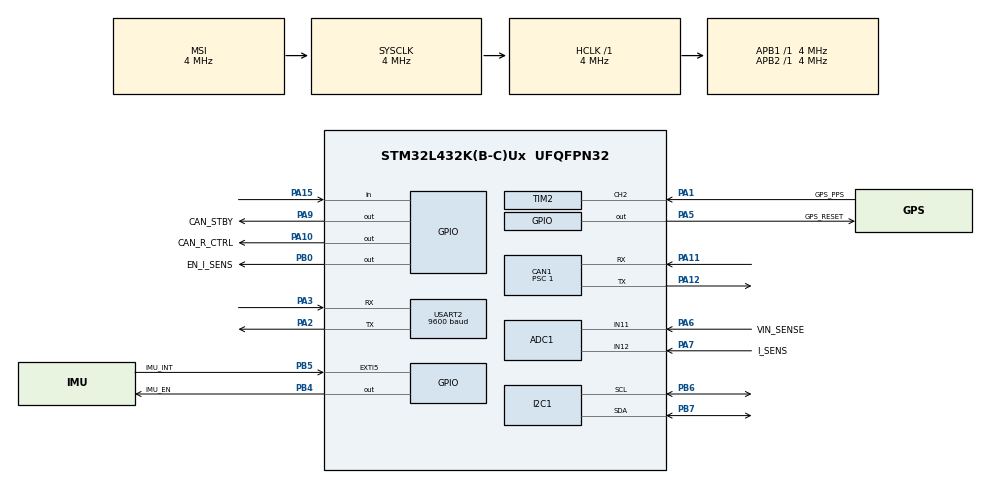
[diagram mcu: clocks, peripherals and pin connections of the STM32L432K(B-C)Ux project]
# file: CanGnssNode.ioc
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ADC1.Channel-0\#ChannelRegularConversion=ADC_CHANNEL_11
ADC1.Channel-1\#ChannelRegularConversion=ADC_CHANNEL_12
ADC1.Channel-2\#ChannelRegularConversion=ADC_CHANNEL_VREFINT
ADC1.Channel-3\#ChannelRegularConversion=ADC_CHANNEL_TEMPSENSOR
ADC1.NbrOfConversion=4
ADC1.NbrOfConversionFlag=1
ADC1.OffsetNumber-0\#ChannelRegularConversion=ADC_OFFSET_NONE
ADC1.OffsetNumber-1\#ChannelRegularConversion=ADC_OFFSET_NONE
ADC1.OffsetNumber-2\#ChannelRegularConversion=ADC_OFFSET_NONE
ADC1.OffsetNumber-3\#ChannelRegularConversion=ADC_OFFSET_NONE
ADC1.OversamplingMode=ENABLE
ADC1.Rank-0\#ChannelRegularConversion=1
ADC1.Rank-1\#ChannelRegularConversion=2
ADC1.Rank-2\#ChannelRegularConversion=3
ADC1.Rank-3\#ChannelRegularConversion=4
ADC1.Ratio=ADC_OVERSAMPLING_RATIO_16
ADC1.RightBitShift=ADC_RIGHTBITSHIFT_2
ADC1.SamplingTime-0\#ChannelRegularConversion=ADC_SAMPLETIME_640CYCLES_5
ADC1.SamplingTime-1\#ChannelRegularConversion=ADC_SAMPLETIME_247CYCLES_5
ADC1.SamplingTime-2\#ChannelRegularConversion=ADC_SAMPLETIME_640CYCLES_5
ADC1.SamplingTime-3\#ChannelRegularConversion=ADC_SAMPLETIME_640CYCLES_5
ADC1.master=1
CAN1.BS1=CAN_BS1_6TQ
CAN1.CalculateBaudRate=500000
CAN1.CalculateTimeBit=2000
CAN1.CalculateTimeQuantum=250.0
CAN1.NART=ENABLE
CAN1.Prescaler=1
CAN1.TTCM=ENABLE
CAN1.TXFP=ENABLE
Dma.ADC1.4.Direction=DMA_PERIPH_TO_MEMORY
Dma.ADC1.4.Instance=DMA1_Channel1
Dma.ADC1.4.MemDataAlignment=DMA_MDATAALIGN_HALFWORD
Dma.ADC1.4.MemInc=DMA_MINC_ENABLE
Dma.ADC1.4.Mode=DMA_NORMAL
Dma.ADC1.4.PeriphDataAlignment=DMA_PDATAALIGN_HALFWORD
Dma.ADC1.4.PeriphInc=DMA_PINC_DISABLE
Dma.ADC1.4.Priority=DMA_PRIORITY_LOW
Dma.I2C1_RX.2.Direction=DMA_PERIPH_TO_MEMORY
Dma.I2C1_RX.2.Instance=DMA2_Channel6
Dma.I2C1_RX.2.MemDataAlignment=DMA_MDATAALIGN_BYTE
Dma.I2C1_RX.2.MemInc=DMA_MINC_ENABLE
Dma.I2C1_RX.2.Mode=DMA_NORMAL
Dma.I2C1_RX.2.PeriphDataAlignment=DMA_PDATAALIGN_BYTE
Dma.I2C1_RX.2.PeriphInc=DMA_PINC_DISABLE
Dma.I2C1_RX.2.Priority=DMA_PRIORITY_LOW
Dma.I2C1_TX.3.Direction=DMA_MEMORY_TO_PERIPH
Dma.I2C1_TX.3.Instance=DMA2_Channel7
Dma.I2C1_TX.3.MemDataAlignment=DMA_MDATAALIGN_BYTE
Dma.I2C1_TX.3.MemInc=DMA_MINC_ENABLE
Dma.I2C1_TX.3.Mode=DMA_NORMAL
Dma.I2C1_TX.3.PeriphDataAlignment=DMA_PDATAALIGN_BYTE
Dma.I2C1_TX.3.PeriphInc=DMA_PINC_DISABLE
Dma.I2C1_TX.3.Priority=DMA_PRIORITY_LOW
Dma.Request0=USART2_RX
Dma.Request1=USART2_TX
Dma.Request2=I2C1_RX
Dma.Request3=I2C1_TX
Dma.Request4=ADC1
Dma.USART2_RX.0.Direction=DMA_PERIPH_TO_MEMORY
Dma.USART2_RX.0.Instance=DMA1_Channel6
Dma.USART2_RX.0.MemDataAlignment=DMA_MDATAALIGN_BYTE
Dma.USART2_RX.0.MemInc=DMA_MINC_ENABLE
Dma.USART2_RX.0.Mode=DMA_CIRCULAR
Dma.USART2_RX.0.PeriphDataAlignment=DMA_PDATAALIGN_BYTE
Dma.USART2_RX.0.PeriphInc=DMA_PINC_DISABLE
Dma.USART2_RX.0.Priority=DMA_PRIORITY_LOW
Dma.USART2_TX.1.Direction=DMA_MEMORY_TO_PERIPH
Dma.USART2_TX.1.Instance=DMA1_Channel7
Dma.USART2_TX.1.MemDataAlignment=DMA_MDATAALIGN_BYTE
Dma.USART2_TX.1.MemInc=DMA_MINC_ENABLE
Dma.USART2_TX.1.Mode=DMA_NORMAL
Dma.USART2_TX.1.PeriphDataAlignment=DMA_PDATAALIGN_BYTE
Dma.USART2_TX.1.PeriphInc=DMA_PINC_DISABLE
Dma.USART2_TX.1.Priority=DMA_PRIORITY_LOW
I2C1.Timing=0x00100D14
Mcu.Family=STM32L4
Mcu.Name=STM32L432K(B-C)Ux
Mcu.Package=UFQFPN32
NVIC.CAN1_RX0_IRQn=true\:0\:0\:false\:false\:true\:true\:true\:true
NVIC.CAN1_SCE_IRQn=true\:1\:0\:true\:false\:true\:true\:true\:true
NVIC.CAN1_TX_IRQn=true\:0\:0\:false\:false\:true\:true\:true\:true
NVIC.DMA1_Channel1_IRQn=true\:3\:0\:true\:false\:true\:false\:true\:true
NVIC.DMA1_Channel6_IRQn=true\:2\:0\:true\:false\:true\:false\:true\:true
NVIC.DMA1_Channel7_IRQn=true\:2\:0\:true\:false\:true\:false\:true\:true
NVIC.DMA2_Channel6_IRQn=true\:3\:0\:true\:false\:true\:false\:true\:true
NVIC.DMA2_Channel7_IRQn=true\:3\:0\:true\:false\:true\:false\:true\:true
NVIC.EXTI9_5_IRQn=true\:2\:0\:true\:false\:true\:true\:true\:true
NVIC.I2C1_ER_IRQn=true\:3\:0\:true\:false\:true\:true\:true\:true
NVIC.I2C1_EV_IRQn=true\:3\:0\:true\:false\:true\:true\:true\:true
NVIC.PriorityGroup=NVIC_PRIORITYGROUP_4
NVIC.TIM2_IRQn=true\:0\:0\:false\:false\:true\:true\:true\:true
NVIC.USART2_IRQn=true\:2\:0\:true\:false\:true\:true\:true\:true
PA1.GPIO_Label=GPS_PPS
PA1.Signal=S_TIM2_CH2
PA10.GPIO_Label=CAN_R_CTRL
PA10.GPIO_PuPd=GPIO_NOPULL
PA10.Signal=GPIO_Output
PA11.Mode=CAN_Activate
PA11.Signal=CAN1_RX
PA12.Mode=CAN_Activate
PA12.Signal=CAN1_TX
PA13\ (JTMS-SWDIO).GPIO_Label=SWDIO
PA13\ (JTMS-SWDIO).Mode=Trace_Asynchronous_SW
PA13\ (JTMS-SWDIO).Signal=SYS_JTMS-SWDIO
PA14\ (JTCK-SWCLK).GPIO_Label=SWCLK
PA14\ (JTCK-SWCLK).Mode=Trace_Asynchronous_SW
PA14\ (JTCK-SWCLK).Signal=SYS_JTCK-SWCLK
PA15\ (JTDI).Signal=GPIO_Input
PA2.Mode=Asynchronous
PA2.Signal=USART2_TX
PA3.Mode=Asynchronous
PA3.Signal=USART2_RX
PA5.GPIO_Label=GPS_RESET
PA5.GPIO_PuPd=GPIO_NOPULL
PA5.Signal=GPIO_Output
PA6.GPIO_Label=VIN_SENSE
PA6.Signal=ADCx_IN11
PA7.GPIO_Label=I_SENS
PA7.Signal=ADCx_IN12
PA9.GPIO_Label=CAN_STBY
PA9.GPIO_PuPd=GPIO_NOPULL
PA9.Signal=GPIO_Output
PB0.GPIO_Label=EN_I_SENS
PB0.GPIO_PuPd=GPIO_NOPULL
PB0.Signal=GPIO_Output
PB3\ (JTDO-TRACESWO).GPIO_Label=SWO
PB3\ (JTDO-TRACESWO).Mode=Trace_Asynchronous_SW
PB3\ (JTDO-TRACESWO).Signal=SYS_JTDO-SWO
PB4\ (NJTRST).GPIO_Label=IMU_EN
PB4\ (NJTRST).GPIO_PuPd=GPIO_NOPULL
PB4\ (NJTRST).Signal=GPIO_Output
PB5.GPIO_Label=IMU_INT
PB5.GPIO_ModeDefaultEXTI=GPIO_MODE_IT_FALLING
PB5.GPIO_PuPd=GPIO_PULLUP
PB5.Signal=GPXTI5
PB6.Mode=I2C
PB6.Signal=I2C1_SCL
PB7.Mode=I2C
PB7.Signal=I2C1_SDA
ProjectManager.HeapSize=0x200
ProjectManager.StackSize=0x400
ProjectManager.TargetToolchain=STM32CubeIDE
RCC.ADCCLockSelection=RCC_ADCCLKSOURCE_SYSCLK
RCC.ADCFreq_Value=4000000
RCC.AHBFreq_Value=4000000
RCC.APB1Freq_Value=4000000
RCC.APB1TimFreq_Value=4000000
RCC.APB2Freq_Value=4000000
RCC.APB2TimFreq_Value=4000000
RCC.CortexFreq_Value=4000000
RCC.HCLKFreq_Value=4000000
RCC.HSE_VALUE=8000000
RCC.HSI48_VALUE=48000000
RCC.HSI_VALUE=16000000
RCC.LSE_VALUE=32768
RCC.MSI_VALUE=4000000
RCC.PWR_Regulator_Voltage_Scale=PWR_REGULATOR_VOLTAGE_SCALE2
RCC.SYSCLKFreq_VALUE=4000000
RCC.USBFreq_Value=16000000
RCC.VCOOutputFreq_Value=32000000
SH.ADCx_IN11.0=ADC1_IN11,IN11-Single-Ended
SH.ADCx_IN12.0=ADC1_IN12,IN12-Single-Ended
SH.S_TIM2_CH2.0=TIM2_CH2,Input_Capture2_from_TI2
TIM2.Channel-Input_Capture2_from_TI2=TIM_CHANNEL_2
TIM2.ICFilter_CH2=4
USART2.BaudRate=9600
USART2.OverrunDisableParam=ADVFEATURE_OVERRUN_DISABLE
USART2.VirtualMode-Asynchronous=VM_ASYNC
VP_ADC1_TempSens_Input.Mode=IN-TempSens
VP_ADC1_Vref_Input.Mode=IN-Vrefint
VP_TIM2_VS_ClockSourceINT.Mode=Internal
board=custom

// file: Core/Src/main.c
/* USER CODE BEGIN Header */
/**
  ******************************************************************************
  * @file           : main.c
  * @brief          : Main program body
  ******************************************************************************
  * @attention
  *
  * Copyright (c) 2026 STMicroelectronics.
  * All rights reserved.
  *
  * This software is licensed under terms that can be found in the LICENSE file
  * in the root directory of this software component.
  * If no LICENSE file comes with this software, it is provided AS-IS.
  *
  ******************************************************************************
  */
/* USER CODE END Header */
#include "main.h"

ADC_HandleTypeDef hadc1;
DMA_HandleTypeDef hdma_adc1;

CAN_HandleTypeDef hcan1;

I2C_HandleTypeDef hi2c1;
DMA_HandleTypeDef hdma_i2c1_rx;
DMA_HandleTypeDef hdma_i2c1_tx;

TIM_HandleTypeDef htim2;

UART_HandleTypeDef huart2;
DMA_HandleTypeDef hdma_usart2_rx;
DMA_HandleTypeDef hdma_usart2_tx;

void SystemClock_Config(void);
static void MX_GPIO_Init(void);
static void MX_DMA_Init(void);
static void MX_ADC1_Init(void);
static void MX_CAN1_Init(void);
static void MX_I2C1_Init(void);
static void MX_USART2_UART_Init(void);
static void MX_TIM2_Init(void);

int main(void)
{

  /* USER CODE BEGIN 1 */
  /* Aplikacja jest zrelokowana za bootloaderem (0x08004000). Tablica wektorow
   * ustawiana przed HAL_Init, zanim wystartuja SysTick i przerwania. Tutaj,
   * a nie w system_stm32l4xx.c, zeby przetrwac regeneracje CubeMX. */
  SCB->VTOR = 0x08004000u;
  /* USER CODE END 1 */

  /* MCU Configuration--------------------------------------------------------*/

  /* Reset of all peripherals, Initializes the Flash interface and the Systick. */
  HAL_Init();

  /* Configure the system clock */
  SystemClock_Config();

  /* Initialize all configured peripherals */
  MX_GPIO_Init();
  MX_DMA_Init();
  MX_ADC1_Init();
  MX_CAN1_Init();
  MX_I2C1_Init();
  MX_USART2_UART_Init();
  MX_TIM2_Init();

  /* Infinite loop */
  while (1)
  {

  }
}

void SystemClock_Config(void)
{
  RCC_OscInitTypeDef RCC_OscInitStruct = {0};
  RCC_ClkInitTypeDef RCC_ClkInitStruct = {0};

  /** Configure the main internal regulator output voltage
  */
  if (HAL_PWREx_ControlVoltageScaling(PWR_REGULATOR_VOLTAGE_SCALE2) != HAL_OK)
  {
    Error_Handler();
  }

  /** Initializes the RCC Oscillators according to the specified parameters
  * in the RCC_OscInitTypeDef structure.
  */
  RCC_OscInitStruct.OscillatorType = RCC_OSCILLATORTYPE_MSI;
  RCC_OscInitStruct.MSIState = RCC_MSI_ON;
  RCC_OscInitStruct.MSICalibrationValue = 0;
  RCC_OscInitStruct.MSIClockRange = RCC_MSIRANGE_6;
  RCC_OscInitStruct.PLL.PLLState = RCC_PLL_NONE;
  if (HAL_RCC_OscConfig(&RCC_OscInitStruct) != HAL_OK)
  {
    Error_Handler();
  }

  /** Initializes the CPU, AHB and APB buses clocks
  */
  RCC_ClkInitStruct.ClockType = RCC_CLOCKTYPE_HCLK|RCC_CLOCKTYPE_SYSCLK
                              |RCC_CLOCKTYPE_PCLK1|RCC_CLOCKTYPE_PCLK2;
  RCC_ClkInitStruct.SYSCLKSource = RCC_SYSCLKSOURCE_MSI;
  RCC_ClkInitStruct.AHBCLKDivider = RCC_SYSCLK_DIV1;
  RCC_ClkInitStruct.APB1CLKDivider = RCC_HCLK_DIV1;
  RCC_ClkInitStruct.APB2CLKDivider = RCC_HCLK_DIV1;

  if (HAL_RCC_ClockConfig(&RCC_ClkInitStruct, FLASH_LATENCY_0) != HAL_OK)
  {
    Error_Handler();
  }
}

static void MX_ADC1_Init(void)
{

  ADC_ChannelConfTypeDef sConfig = {0};

  /** Common config
  */
  hadc1.Instance = ADC1;
  hadc1.Init.ClockPrescaler = ADC_CLOCK_ASYNC_DIV1;
  hadc1.Init.Resolution = ADC_RESOLUTION_12B;
  hadc1.Init.DataAlign = ADC_DATAALIGN_RIGHT;
  hadc1.Init.ScanConvMode = ADC_SCAN_ENABLE;
  hadc1.Init.EOCSelection = ADC_EOC_SINGLE_CONV;
  hadc1.Init.LowPowerAutoWait = DISABLE;
  hadc1.Init.ContinuousConvMode = DISABLE;
  hadc1.Init.NbrOfConversion = 4;
  hadc1.Init.DiscontinuousConvMode = DISABLE;
  hadc1.Init.ExternalTrigConv = ADC_SOFTWARE_START;
  hadc1.Init.ExternalTrigConvEdge = ADC_EXTERNALTRIGCONVEDGE_NONE;
  hadc1.Init.DMAContinuousRequests = DISABLE;
  hadc1.Init.Overrun = ADC_OVR_DATA_PRESERVED;
  hadc1.Init.OversamplingMode = ENABLE;
  hadc1.Init.Oversampling.Ratio = ADC_OVERSAMPLING_RATIO_16;
  hadc1.Init.Oversampling.RightBitShift = ADC_RIGHTBITSHIFT_2;
  hadc1.Init.Oversampling.TriggeredMode = ADC_TRIGGEREDMODE_SINGLE_TRIGGER;
  hadc1.Init.Oversampling.OversamplingStopReset = ADC_REGOVERSAMPLING_CONTINUED_MODE;
  if (HAL_ADC_Init(&hadc1) != HAL_OK)
  {
    Error_Handler();
  }

  /** Configure Regular Channel
  */
  sConfig.Channel = ADC_CHANNEL_11;
  sConfig.Rank = ADC_REGULAR_RANK_1;
  sConfig.SamplingTime = ADC_SAMPLETIME_640CYCLES_5;
  sConfig.SingleDiff = ADC_SINGLE_ENDED;
  sConfig.OffsetNumber = ADC_OFFSET_NONE;
  sConfig.Offset = 0;
  if (HAL_ADC_ConfigChannel(&hadc1, &sConfig) != HAL_OK)
  {
    Error_Handler();
  }

  /** Configure Regular Channel
  */
  sConfig.Channel = ADC_CHANNEL_12;
  sConfig.Rank = ADC_REGULAR_RANK_2;
  sConfig.SamplingTime = ADC_SAMPLETIME_247CYCLES_5;
  if (HAL_ADC_ConfigChannel(&hadc1, &sConfig) != HAL_OK)
  {
    Error_Handler();
  }

  /** Configure Regular Channel
  */
  sConfig.Channel = ADC_CHANNEL_VREFINT;
  sConfig.Rank = ADC_REGULAR_RANK_3;
  sConfig.SamplingTime = ADC_SAMPLETIME_640CYCLES_5;
  if (HAL_ADC_ConfigChannel(&hadc1, &sConfig) != HAL_OK)
  {
    Error_Handler();
  }

  /** Configure Regular Channel
  */
  sConfig.Channel = ADC_CHANNEL_TEMPSENSOR;
  sConfig.Rank = ADC_REGULAR_RANK_4;
  if (HAL_ADC_ConfigChannel(&hadc1, &sConfig) != HAL_OK)
  {
    Error_Handler();
  }

}

static void MX_CAN1_Init(void)
{

  hcan1.Instance = CAN1;
  hcan1.Init.Prescaler = 1;
  hcan1.Init.Mode = CAN_MODE_NORMAL;
  hcan1.Init.SyncJumpWidth = CAN_SJW_1TQ;
  hcan1.Init.TimeSeg1 = CAN_BS1_6TQ;
  hcan1.Init.TimeSeg2 = CAN_BS2_1TQ;
  hcan1.Init.TimeTriggeredMode = ENABLE;
  hcan1.Init.AutoBusOff = DISABLE;
  hcan1.Init.AutoWakeUp = DISABLE;
  hcan1.Init.AutoRetransmission = ENABLE;
  hcan1.Init.ReceiveFifoLocked = DISABLE;
  hcan1.Init.TransmitFifoPriority = ENABLE;
  if (HAL_CAN_Init(&hcan1) != HAL_OK)
  {
    Error_Handler();
  }

}

static void MX_I2C1_Init(void)
{

  hi2c1.Instance = I2C1;
  hi2c1.Init.Timing = 0x00100D14;
  hi2c1.Init.OwnAddress1 = 0;
  hi2c1.Init.AddressingMode = I2C_ADDRESSINGMODE_7BIT;
  hi2c1.Init.DualAddressMode = I2C_DUALADDRESS_DISABLE;
  hi2c1.Init.OwnAddress2 = 0;
  hi2c1.Init.OwnAddress2Masks = I2C_OA2_NOMASK;
  hi2c1.Init.GeneralCallMode = I2C_GENERALCALL_DISABLE;
  hi2c1.Init.NoStretchMode = I2C_NOSTRETCH_DISABLE;
  if (HAL_I2C_Init(&hi2c1) != HAL_OK)
  {
    Error_Handler();
  }

  /** Configure Analogue filter
  */
  if (HAL_I2CEx_ConfigAnalogFilter(&hi2c1, I2C_ANALOGFILTER_ENABLE) != HAL_OK)
  {
    Error_Handler();
  }

  /** Configure Digital filter
  */
  if (HAL_I2CEx_ConfigDigitalFilter(&hi2c1, 0) != HAL_OK)
  {
    Error_Handler();
  }

}

static void MX_TIM2_Init(void)
{

  TIM_ClockConfigTypeDef sClockSourceConfig = {0};
  TIM_MasterConfigTypeDef sMasterConfig = {0};
  TIM_IC_InitTypeDef sConfigIC = {0};

  htim2.Instance = TIM2;
  htim2.Init.Prescaler = 0;
  htim2.Init.CounterMode = TIM_COUNTERMODE_UP;
  htim2.Init.Period = 4294967295;
  htim2.Init.ClockDivision = TIM_CLOCKDIVISION_DIV1;
  htim2.Init.AutoReloadPreload = TIM_AUTORELOAD_PRELOAD_DISABLE;
  if (HAL_TIM_Base_Init(&htim2) != HAL_OK)
  {
    Error_Handler();
  }
  sClockSourceConfig.ClockSource = TIM_CLOCKSOURCE_INTERNAL;
  if (HAL_TIM_ConfigClockSource(&htim2, &sClockSourceConfig) != HAL_OK)
  {
    Error_Handler();
  }
  if (HAL_TIM_IC_Init(&htim2) != HAL_OK)
  {
    Error_Handler();
  }
  sMasterConfig.MasterOutputTrigger = TIM_TRGO_RESET;
  sMasterConfig.MasterSlaveMode = TIM_MASTERSLAVEMODE_DISABLE;
  if (HAL_TIMEx_MasterConfigSynchronization(&htim2, &sMasterConfig) != HAL_OK)
  {
    Error_Handler();
  }
  sConfigIC.ICPolarity = TIM_INPUTCHANNELPOLARITY_RISING;
  sConfigIC.ICSelection = TIM_ICSELECTION_DIRECTTI;
  sConfigIC.ICPrescaler = TIM_ICPSC_DIV1;
  sConfigIC.ICFilter = 4;
  if (HAL_TIM_IC_ConfigChannel(&htim2, &sConfigIC, TIM_CHANNEL_2) != HAL_OK)
  {
    Error_Handler();
  }

}

static void MX_USART2_UART_Init(void)
{

  huart2.Instance = USART2;
  huart2.Init.BaudRate = 9600;
  huart2.Init.WordLength = UART_WORDLENGTH_8B;
  huart2.Init.StopBits = UART_STOPBITS_1;
  huart2.Init.Parity = UART_PARITY_NONE;
  huart2.Init.Mode = UART_MODE_TX_RX;
  huart2.Init.HwFlowCtl = UART_HWCONTROL_NONE;
  huart2.Init.OverSampling = UART_OVERSAMPLING_16;
  huart2.Init.OneBitSampling = UART_ONE_BIT_SAMPLE_DISABLE;
  huart2.AdvancedInit.AdvFeatureInit = UART_ADVFEATURE_RXOVERRUNDISABLE_INIT;
  huart2.AdvancedInit.OverrunDisable = UART_ADVFEATURE_OVERRUN_DISABLE;
  if (HAL_UART_Init(&huart2) != HAL_OK)
  {
    Error_Handler();
  }

}

static void MX_DMA_Init(void)
{

  /* DMA controller clock enable */
  __HAL_RCC_DMA1_CLK_ENABLE();
  __HAL_RCC_DMA2_CLK_ENABLE();

  /* DMA interrupt init */
  /* DMA1_Channel1_IRQn interrupt configuration */
  HAL_NVIC_SetPriority(DMA1_Channel1_IRQn, 3, 0);
  HAL_NVIC_EnableIRQ(DMA1_Channel1_IRQn);
  /* DMA1_Channel6_IRQn interrupt configuration */
  HAL_NVIC_SetPriority(DMA1_Channel6_IRQn, 2, 0);
  HAL_NVIC_EnableIRQ(DMA1_Channel6_IRQn);
  /* DMA1_Channel7_IRQn interrupt configuration */
  HAL_NVIC_SetPriority(DMA1_Channel7_IRQn, 2, 0);
  HAL_NVIC_EnableIRQ(DMA1_Channel7_IRQn);
  /* DMA2_Channel6_IRQn interrupt configuration */
  HAL_NVIC_SetPriority(DMA2_Channel6_IRQn, 3, 0);
  HAL_NVIC_EnableIRQ(DMA2_Channel6_IRQn);
  /* DMA2_Channel7_IRQn interrupt configuration */
  HAL_NVIC_SetPriority(DMA2_Channel7_IRQn, 3, 0);
  HAL_NVIC_EnableIRQ(DMA2_Channel7_IRQn);

}

static void MX_GPIO_Init(void)
{
  GPIO_InitTypeDef GPIO_InitStruct = {0};

  /* GPIO Ports Clock Enable */
  __HAL_RCC_GPIOA_CLK_ENABLE();
  __HAL_RCC_GPIOB_CLK_ENABLE();

  /*Configure GPIO pin Output Level */
  HAL_GPIO_WritePin(GPIOA, GPS_RESET_Pin|CAN_STBY_Pin|CAN_R_CTRL_Pin, GPIO_PIN_RESET);

  /*Configure GPIO pin Output Level */
  HAL_GPIO_WritePin(GPIOB, EN_I_SENS_Pin|IMU_EN_Pin, GPIO_PIN_RESET);

  /*Configure GPIO pins : GPS_RESET_Pin CAN_STBY_Pin CAN_R_CTRL_Pin */
  GPIO_InitStruct.Pin = GPS_RESET_Pin|CAN_STBY_Pin|CAN_R_CTRL_Pin;
  GPIO_InitStruct.Mode = GPIO_MODE_OUTPUT_PP;
  GPIO_InitStruct.Pull = GPIO_NOPULL;
  GPIO_InitStruct.Speed = GPIO_SPEED_FREQ_LOW;
  HAL_GPIO_Init(GPIOA, &GPIO_InitStruct);

  /*Configure GPIO pins : EN_I_SENS_Pin IMU_EN_Pin */
  GPIO_InitStruct.Pin = EN_I_SENS_Pin|IMU_EN_Pin;
  GPIO_InitStruct.Mode = GPIO_MODE_OUTPUT_PP;
  GPIO_InitStruct.Pull = GPIO_NOPULL;
  GPIO_InitStruct.Speed = GPIO_SPEED_FREQ_LOW;
  HAL_GPIO_Init(GPIOB, &GPIO_InitStruct);

  /*Configure GPIO pin : PA15 */
  GPIO_InitStruct.Pin = GPIO_PIN_15;
  GPIO_InitStruct.Mode = GPIO_MODE_INPUT;
  GPIO_InitStruct.Pull = GPIO_NOPULL;
  HAL_GPIO_Init(GPIOA, &GPIO_InitStruct);

  /*Configure GPIO pin : IMU_INT_Pin */
  GPIO_InitStruct.Pin = IMU_INT_Pin;
  GPIO_InitStruct.Mode = GPIO_MODE_IT_FALLING;
  GPIO_InitStruct.Pull = GPIO_PULLUP;
  HAL_GPIO_Init(IMU_INT_GPIO_Port, &GPIO_InitStruct);

  /* EXTI interrupt init*/
  HAL_NVIC_SetPriority(EXTI9_5_IRQn, 2, 0);
  HAL_NVIC_EnableIRQ(EXTI9_5_IRQn);

}

void Error_Handler(void)
{
  __disable_irq();
  while (1)
  {
  }
}
